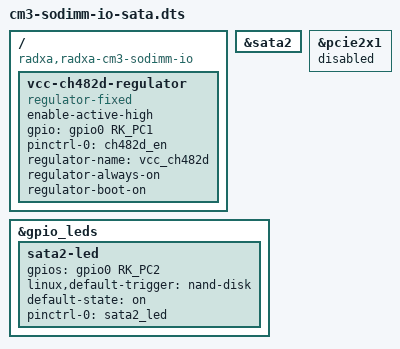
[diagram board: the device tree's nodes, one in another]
/dts-v1/;
/plugin/;
#include <dt-bindings/gpio/gpio.h>
#include <dt-bindings/pinctrl/rockchip.h>

/ {
	compatible = "radxa,radxa-cm3-sodimm-io", "rockchip,rk3566";

	fragment@0 {
		target-path = "/";

		__overlay__ {
			vcc-ch482d-regulator {
				compatible = "regulator-fixed";
				enable-active-high;
				gpio = <&gpio0 RK_PC1 GPIO_ACTIVE_HIGH>;
				pinctrl-names = "default";
				pinctrl-0 = <&ch482d_en>;
				regulator-name = "vcc_ch482d";
				regulator-always-on;
				regulator-boot-on;
			};
		};
	};

	fragment@1 {
		target = <&sata2>;

		__overlay__ {
			status = "okay";
		};
	};

	fragment@2 {
		target = <&gpio_leds>;

		__overlay__ {
			sata2-led {
				gpios = <&gpio0 RK_PC2 GPIO_ACTIVE_HIGH>;
				linux,default-trigger = "nand-disk";
				default-state = "on";
				pinctrl-0 = <&sata2_led>;
			};
		};
	};

	fragment@3 {
		target = <&pcie2x1>;

		__overlay__ {
			status = "disabled";
		};
	};
};
